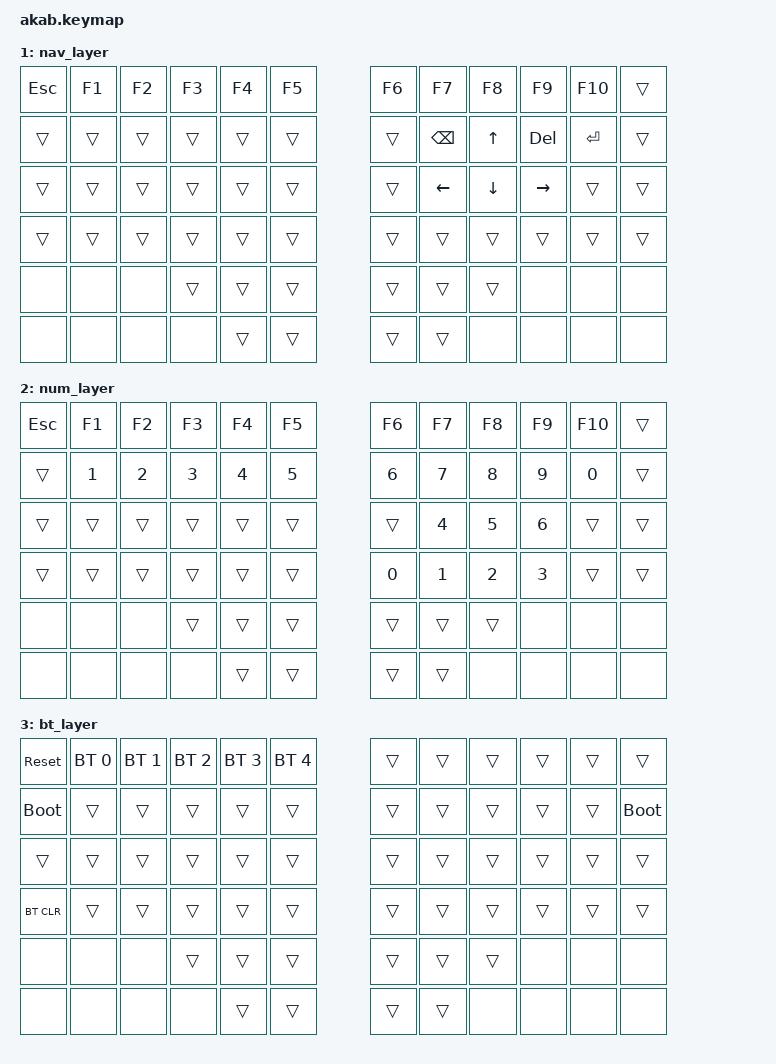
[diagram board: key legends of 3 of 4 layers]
#include <behaviors.dtsi>      
#include <dt-bindings/zmk/keys.h>
#include <dt-bindings/zmk/bt.h>

#define BASE    0
#define NAV     1
#define NUM     2
#define BT      3
/ {

    combos {
        compatible = "zmk,combos";
        combo_reset_left {
            timeout-ms = <50>;
            key-positions = <0 5>;  // left side keys (grave + E5)
            bindings = <&sys_reset>;
        };
        combo_reset_right {
            timeout-ms = <50>;
            key-positions = <6 11>;  // right side keys (N6 + -)
            bindings = <&sys_reset>;
        };
    };

    keymap {
        compatible = "zmk,keymap";

            default_layer {
                bindings = <
        &kp GRAVE   &kp N1  &kp N2  &kp N3      &kp N4      &kp N5                          &kp N6      &kp N7      &kp N8      &kp N9      &kp N0      &kp MINUS
        &kp TAB     &kp Q   &kp W   &kp E       &kp R       &kp T                           &kp Y       &kp U       &kp I       &kp O       &kp P       &kp BSLH
        &kp LSHFT   &kp A   &kp S   &kp D       &kp F       &kp G                           &kp H       &kp J       &kp K       &kp L       &kp SQT     &kp RSHFT
        &kp LCTRL   &kp Z   &kp X   &kp C       &kp V       &kp B                           &kp N       &kp M       &kp COMMA   &kp DOT     &kp FSLH    &kp RCTRL
                                    &kp LGUI    &kp LALT    &mo BT                          &mo NAV     &kp SPACE   &mo NUM
                                                &kp LCTRL   &kp SPACE                       &trans      &trans
                >;
            };

        nav_layer {
            bindings = <
        &kp ESC     &kp F1      &kp F2      &kp F3      &kp F4      &kp F5                  &kp F6      &kp F7      &kp F8      &kp F9      &kp F10     &trans
        &trans      &trans      &trans      &trans      &trans      &trans                  &trans      &kp BSPC    &kp UP      &kp DEL     &kp RET     &trans
        &trans      &trans      &trans      &trans      &trans      &trans                  &trans      &kp LEFT    &kp DOWN    &kp RIGHT   &trans      &trans
        &trans      &trans      &trans      &trans      &trans      &trans                  &trans      &trans      &trans      &trans      &trans      &trans
        &none       &none       &none       &trans      &trans      &trans                  &trans      &trans      &trans      &none       &none       &none
        &none       &none       &none       &none       &trans      &trans                  &trans      &trans      &none       &none       &none       &none
            >;
        };

        num_layer {
            bindings = <
        &kp ESC     &kp F1      &kp F2      &kp F3      &kp F4      &kp F5                  &kp F6      &kp F7      &kp F8      &kp F9      &kp F10     &trans
        &trans      &kp N1      &kp N2      &kp N3      &kp N4      &kp N5                  &kp N6      &kp N7      &kp N8      &kp N9      &kp N0      &trans
        &trans      &trans      &trans      &trans      &trans      &trans                  &trans      &kp N4      &kp N5      &kp N6      &trans      &trans
        &trans      &trans      &trans      &trans      &trans      &trans                  &kp N0      &kp N1      &kp N2      &kp N3      &trans      &trans
        &none       &none       &none       &trans      &trans      &trans                  &trans      &trans      &trans      &none       &none       &none
        &none       &none       &none       &none       &trans      &trans                  &trans      &trans      &none       &none       &none       &none
            >;
        };

        bt_layer {
            bindings = <
        &sys_reset  &bt BT_SEL 0    &bt BT_SEL 1    &bt BT_SEL 2    &bt BT_SEL 3    &bt BT_SEL 4    &trans      &trans      &trans      &trans      &trans      &trans
        &bootloader &trans          &trans          &trans          &trans          &trans          &trans      &trans      &trans      &trans      &trans      &bootloader
        &trans      &trans          &trans          &trans          &trans          &trans          &trans      &trans      &trans      &trans      &trans      &trans
        &bt BT_CLR  &trans          &trans          &trans          &trans          &trans          &trans      &trans      &trans      &trans      &trans      &trans
        &none       &none           &none           &trans          &trans          &trans          &trans      &trans      &trans      &none       &none       &none
        &none       &none           &none           &none           &trans          &trans          &trans      &trans      &none       &none       &none       &none
            >;
        };
    };
};
